# ATSAM4LC4C register map
Vendor: Atmel Corporation; Series: SAM4L; File version: B
CPU: CM4 r0p1, little endian, MPU, no FPU, 4 interrupt priority bits
Registers are 32-bit, write-only, reset 0x0 unless marked. A register's access mark holds for its fields unless they carry their own. Offsets are from the block's base; [hi:lo] are bit positions; 'fields as' and 'values as' point back to an identical list.

## TWIS0 — Two-wire Slave Interface 0
Base 0x40018400; register names take the prefix TWIS_
Same registers: TWIS1 0x4001C400
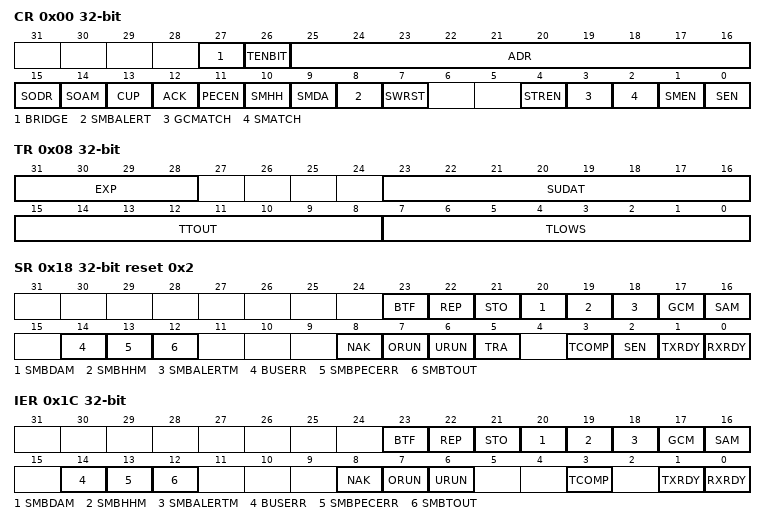
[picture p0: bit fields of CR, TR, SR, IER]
0x00 CR rw — Control Register
  [27] BRIDGE — Bridge Control Enable
  [26] TENBIT — Ten Bit Address Match
  [25:16] ADR — Slave Address
  [15] SODR — Stretch Clock on Data Byte Reception
  [14] SOAM — Stretch Clock on Address Match
  [13] CUP — NBYTES Count Up
  [12] ACK — Slave Receiver Data Phase ACK Value
  [11] PECEN — Packet Error Checking Enable
  [10] SMHH — SMBus Host Header
  [9] SMDA — SMBus Default Address
  [8] SMBALERT — SMBus Alert
  [7] SWRST — Software Reset
  [4] STREN — Clock Stretch Enable
  [3] GCMATCH — General Call Address Match
  [2] SMATCH — Slave Address Match
  [1] SMEN — SMBus Mode Enable
  [0] SEN — Slave Enable
0x04 NBYTES rw
  [7:0] NBYTES — Number of Bytes to Transfer
0x08 TR rw — Timing Register
  [31:28] EXP — Clock Prescaler
  [23:16] SUDAT — Data Setup Cycles
  [15:8] TTOUT — SMBus Ttimeout Cycles
  [7:0] TLOWS — SMBus Tlow:sext Cycles
0x0C RHR ro — Receive Holding Register
  [7:0] RXDATA — Received Data Byte
0x10 THR — Transmit Holding Register
  [7:0] TXDATA — Data Byte to Transmit
0x14 PECR ro — Packet Error Check Register
  [7:0] PEC — Calculated PEC Value
0x18 SR ro reset 0x2 — Status Register
  [23] BTF — Byte Transfer Finished
  [22] REP — Repeated Start Received
  [21] STO — Stop Received
  [20] SMBDAM — SMBus Default Address Match
  [19] SMBHHM — SMBus Host Header Address Match
  [18] SMBALERTM — SMBus Alert Response Address Match
  [17] GCM — General Call Match
  [16] SAM — Slave Address Match
  [14] BUSERR — Bus Error
  [13] SMBPECERR — SMBus PEC Error
  [12] SMBTOUT — SMBus Timeout
  [8] NAK — NAK Received
  [7] ORUN — Overrun
  [6] URUN — Underrun
  [5] TRA — Transmitter Mode
  [3] TCOMP — Transmission Complete
  [2] SEN — Slave Enabled
  [1] TXRDY — TX Buffer Ready
  [0] RXRDY — RX Buffer Ready
0x1C IER — Interrupt Enable Register
  [23] BTF — Byte Transfer Finished
  [22] REP — Repeated Start Received
  [21] STO — Stop Received
  [20] SMBDAM — SMBus Default Address Match
  [19] SMBHHM — SMBus Host Header Address Match
  [18] SMBALERTM — SMBus Alert Response Address Match
  [17] GCM — General Call Match
  [16] SAM — Slave Address Match
  [14] BUSERR — Bus Error
  [13] SMBPECERR — SMBus PEC Error
  [12] SMBTOUT — SMBus Timeout
  [8] NAK — NAK Received
  [7] ORUN — Overrun
  [6] URUN — Underrun
  [3] TCOMP — Transmission Complete
  [1] TXRDY — TX Buffer Ready
  [0] RXRDY — RX Buffer Ready
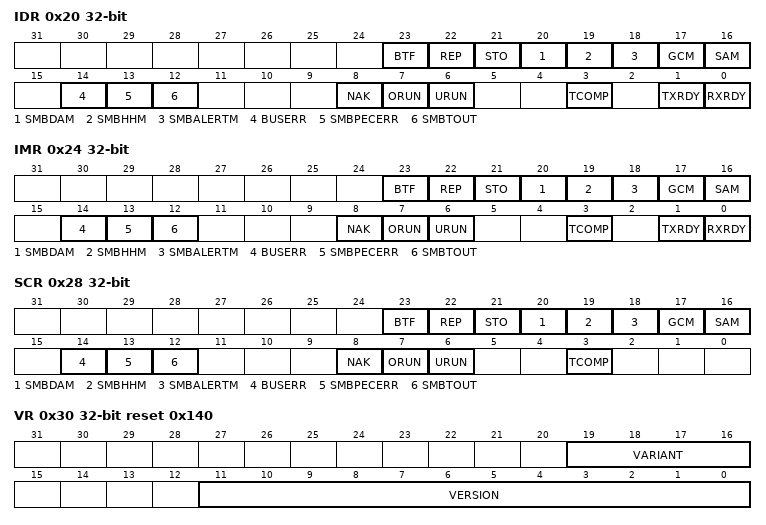
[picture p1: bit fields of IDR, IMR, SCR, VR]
0x20 IDR — Interrupt Disable Register
  fields as IER
0x24 IMR ro — Interrupt Mask Register
  fields as IER
0x28 SCR — Status Clear Register
  [23] BTF — Byte Transfer Finished
  [22] REP — Repeated Start Received
  [21] STO — Stop Received
  [20] SMBDAM — SMBus Default Address Match
  [19] SMBHHM — SMBus Host Header Address Match
  [18] SMBALERTM — SMBus Alert Response Address Match
  [17] GCM — General Call Match
  [16] SAM — Slave Address Match
  [14] BUSERR — Bus Error
  [13] SMBPECERR — SMBus PEC Error
  [12] SMBTOUT — SMBus Timeout
  [8] NAK — NAK Received
  [7] ORUN — Overrun
  [6] URUN — Underrun
  [3] TCOMP — Transmission Complete
0x2C PR ro reset 0x1 — Parameter Register
  [0] HS — HS-mode
0x30 VR ro reset 0x140 — Version Register
  [19:16] VARIANT — Variant Number
  [11:0] VERSION — Version Number
0x34 HSTR rw — HS-mode Timing Register
  [23:16] HDDAT — Data Hold Cycles
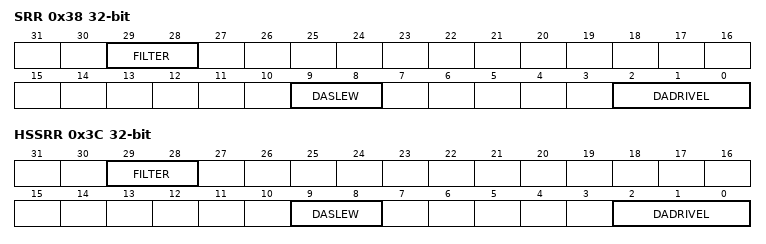
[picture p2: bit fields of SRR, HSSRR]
0x38 SRR rw — Slew Rate Register
  [29:28] FILTER — Input Spike Filter Control
  [9:8] DASLEW — Data Slew Limit
  [2:0] DADRIVEL — Data Drive Strength LOW
0x3C HSSRR rw — HS-mode Slew Rate Register
  fields as SRR

## Notices in the file
Atmel Microcontroller Software Support
Copyright (c) 2014, Atmel Corporation
All rights reserved.
Redistribution and use in source and binary forms, with or without
modification, are permitted provided that the following condition is met:
- Redistributions of source code must retain the above copyright notice,
this list of conditions and the disclaimer below.
Atmel's name may not be used to endorse or promote products derived from
this software without specific prior written permission.
DISCLAIMER: THIS SOFTWARE IS PROVIDED BY ATMEL "AS IS" AND ANY EXPRESS OR
IMPLIED WARRANTIES, INCLUDING, BUT NOT LIMITED TO, THE IMPLIED WARRANTIES OF
MERCHANTABILITY, FITNESS FOR A PARTICULAR PURPOSE AND NON-INFRINGEMENT ARE
DISCLAIMED. IN NO EVENT SHALL ATMEL BE LIABLE FOR ANY DIRECT, INDIRECT,
INCIDENTAL, SPECIAL, EXEMPLARY, OR CONSEQUENTIAL DAMAGES (INCLUDING, BUT NOT
LIMITED TO, PROCUREMENT OF SUBSTITUTE GOODS OR SERVICES; LOSS OF USE, DATA,
OR PROFITS; OR BUSINESS INTERRUPTION) HOWEVER CAUSED AND ON ANY THEORY OF
LIABILITY, WHETHER IN CONTRACT, STRICT LIABILITY, OR TORT (INCLUDING
NEGLIGENCE OR OTHERWISE) ARISING IN ANY WAY OUT OF THE USE OF THIS SOFTWARE,
EVEN IF ADVISED OF THE POSSIBILITY OF SUCH DAMAGE.
